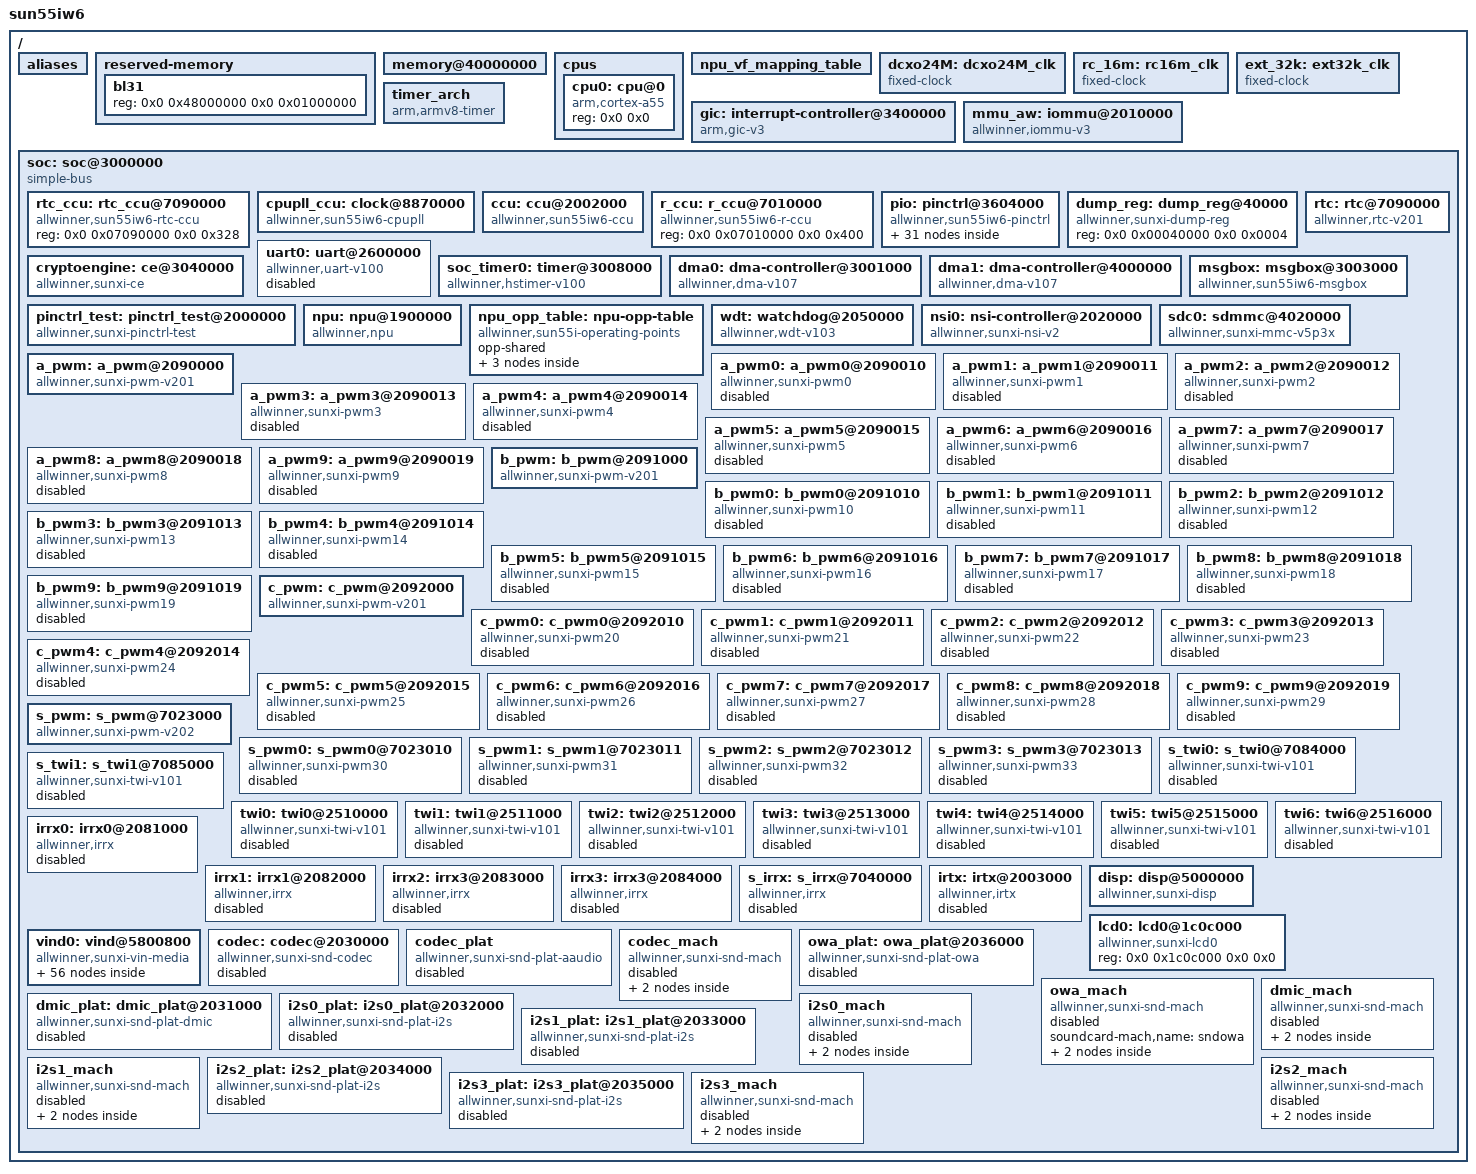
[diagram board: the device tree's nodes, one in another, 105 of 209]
// SPDX-License-Identifier: (GPL-2.0+ or MIT)
#include <dt-bindings/clock/sun55iw6-ccu.h>
#include <dt-bindings/clock/sun55iw6-rtc.h>
#include <dt-bindings/clock/sun55iw6-r-ccu.h>
#include <dt-bindings/gpio/gpio.h>
#include <dt-bindings/gpio/sun4i-gpio.h>
#include <dt-bindings/interrupt-controller/arm-gic.h>
#include <dt-bindings/reset/sun55iw6-ccu.h>
#include <dt-bindings/reset/sun55iw6-r-ccu.h>
#include <dt-bindings/power/a523-power.h>
#include <dt-bindings/phy/phy.h>
#include <dt-bindings/thermal/thermal.h>

/ {
	model = "sun55iw6";
	interrupt-parent = <&gic>;
	#address-cells = <2>;
	#size-cells = <2>;

	aliases {
		serial0 = &uart0;
		twi0 = &twi0;
		twi1 = &twi1;
		twi2 = &twi2;
		twi3 = &twi3;
		twi4 = &twi4;
		twi5 = &twi5;
		twi6 = &twi6;
		twi7 = &s_twi0;
		twi8 = &s_twi1;
		ir0 = &irrx0;
		ir1 = &irrx1;
		ir2 = &irrx2;
		ir3 = &irrx3;
		ir4 = &s_irrx;
	};

	reserved-memory {
		#address-cells = <2>;
		#size-cells = <2>;
		ranges;

		bl31 {
			reg = <0x0 0x48000000 0x0 0x01000000>;
		};
	};

	/* avoid panic when memory-node err(from uboot) */
	memory@40000000 {
		device_type = "memory";
		reg = <0x00000000 0x40000000 0x00000000 0x20000000>;
	};

	cpus {
		#address-cells = <2>;
		#size-cells = <0>;

		cpu0: cpu@0 {
			device_type = "cpu";
			compatible = "arm,cortex-a55";
			reg = <0x0 0x0>;
		};
	};

	npu_vf_mapping_table: npu_vf_mapping_table {
		table = <
			0x01 1
			0x02 2
			0x12 21
			0x04 3
			0x14 31
			0x05 4
			0x06 5
			>;
	};

	dcxo24M: dcxo24M_clk {
		#clock-cells = <0>;
		compatible = "fixed-clock";
		clock-frequency = <24000000>;
		clock-output-names = "dcxo24M";
	};

	rc_16m: rc16m_clk {
		#clock-cells = <0>;
		compatible = "fixed-clock";
		clock-frequency = <16000000>;
		clock-accuracy = <300000000>;
		clock-output-names = "rc-16m";
	};

	ext_32k: ext32k_clk {
		#clock-cells = <0>;
		compatible = "fixed-clock";
		clock-frequency = <32768>;
		clock-output-names = "ext-32k";
	};

	gic: interrupt-controller@3400000 {
		compatible = "arm,gic-v3";
		#interrupt-cells = <3>;
		#address-cells = <0>;
		interrupt-controller;
		reg = <0x0 0x03400000 0 0x10000>, /* GIC Dist */
		      <0x0 0x03460000 0 0xFF004>; /* GIC Re */
		interrupt-parent = <&gic>;
	};

	timer_arch {
		compatible = "arm,armv8-timer";
		interrupts = <GIC_PPI 13 (GIC_CPU_MASK_SIMPLE(4) | IRQ_TYPE_LEVEL_LOW)>,
			   <GIC_PPI 14 (GIC_CPU_MASK_SIMPLE(4) | IRQ_TYPE_LEVEL_LOW)>,
			   <GIC_PPI 11 (GIC_CPU_MASK_SIMPLE(4) | IRQ_TYPE_LEVEL_LOW)>,
			   <GIC_PPI 10 (GIC_CPU_MASK_SIMPLE(4) | IRQ_TYPE_LEVEL_LOW)>;
		clock-frequency = <24000000>;
		interrupt-parent = <&gic>;
		arm,no-tick-in-suspend;
	};

	mmu_aw: iommu@2010000 {
		compatible = "allwinner,iommu-v3";
		reg = <0x0 0x02010000 0x0 0x1000>;
		interrupts = <GIC_SPI 65 IRQ_TYPE_LEVEL_HIGH>;
		interrupt-names = "iommu-irq";
		clocks = <&ccu CLK_IOMMU>;
		clock-names = "iommu";
		/* clock-frequency = <24000000>; */
		#iommu-cells = <2>;
		version=<0x17>;
		tlb_prefetch = <0x3007f>;
		tlb_invalid_mode = <0x1>;
		ptw_invalid_mode = <0x1>;
		masters = "ISP", "CSI", "VE0", "RESERVED", "G2D",
			"DE", "E907", "DEBUG_MODE";
		valid_masters=<7>;
	};

	soc: soc@3000000 {
		compatible = "simple-bus";
		#address-cells = <2>;
		#size-cells = <2>;
		ranges;

		rtc_ccu: rtc_ccu@7090000 {
			compatible = "allwinner,sun55iw6-rtc-ccu";
			reg = <0x0 0x07090000 0x0 0x328>;
			#clock-cells = <1>;
			#reset-cells = <1>;
		};

		cpupll_ccu: clock@8870000 {
			compatible = "allwinner,sun55iw6-cpupll";
			reg = <0x0 0x08870000 0x0 0x4000>;
			#clock-cells = <1>;
			#reset-cells = <1>;
			pll_step = <0x9>;
			/* pll_ssc will divid pll_ssc_scale in code
			 * keep value 0 < pll_ssc < 10
			 */
			pll_ssc_scale = <0xa>;
			pll_ssc = <0x1>;
		};

		ccu: ccu@2002000 {
			compatible = "allwinner,sun55iw6-ccu";
			reg = <0x0 0x02002000 0x0 0x2000>;
			clocks = <&dcxo24M>, <&rtc_ccu CLK_OSC32K>, <&rc_16m>;
			clock-names = "hosc", "losc", "iosc";
			#clock-cells = <1>;
			#reset-cells = <1>;
		};

		r_ccu: r_ccu@7010000 {
			compatible = "allwinner,sun55iw6-r-ccu";
			reg = <0x0 0x07010000 0x0 0x400>;
			#clock-cells = <1>;
			#reset-cells = <1>;
		};

		pio: pinctrl@3604000 {
			//#address-cells = <1>;
			//#size-cells = <0>;
			compatible = "allwinner,sun55iw6-pinctrl";
			reg = <0x0 0x03604000 0x0 0x600>;
			interrupts = <GIC_SPI 67 IRQ_TYPE_LEVEL_HIGH>,
				     <GIC_SPI 69 IRQ_TYPE_LEVEL_HIGH>,
				     <GIC_SPI 71 IRQ_TYPE_LEVEL_HIGH>,
				     <GIC_SPI 73 IRQ_TYPE_LEVEL_HIGH>,
				     <GIC_SPI 77 IRQ_TYPE_LEVEL_HIGH>,
				     <GIC_SPI 79 IRQ_TYPE_LEVEL_HIGH>;
			clocks = <&ccu CLK_APB1>, <&dcxo24M>, <&rtc_ccu CLK_OSC32K>;
			clock-names = "apb", "hosc", "losc";
			gpio-controller;
			#gpio-cells = <3>;
			interrupt-controller;
			#interrupt-cells = <3>;

			test_pins_a: test_pins@0 {
				pins = "PB0", "PB1";
				function = "test";
				drive-strength = <10>;
				bias-pull-up;
			};

			test_pins_b: test_pins@1 {
				pins = "PB0", "PB1";
				function = "gpio_in";
			};

			sdc0_pins_a: sdc0@0 {
				pins = "PF0", "PF1", "PF2",
						"PF3", "PF4", "PF5";
				function = "sdc0";
				drive-strength = <40>;
				bias-pull-up;
				power-source = <3300>;
			};

			sdc0_pins_b: sdc0@1 {
				pins = "PF0", "PF1", "PF2",
						"PF3", "PF4", "PF5";
				function = "sdc0";
				drive-strength = <40>;
				bias-pull-up;
				power-source = <1800>;
			};

			sdc0_pins_c: sdc0@2 {
				pins = "PF0", "PF1", "PF2",
				"PF3", "PF4", "PF5";
				function = "gpio_in";
			};

			/* TODO: add jtag pin */
			sdc0_pins_d: sdc0@3 {
				pins = "PF2", "PF4";
				function = "uart0";
				drive-strength = <10>;
				bias-pull-up;
			};

			sdc0_pins_e: sdc0@4 {
				pins = "PF0", "PF1", "PF3",
						"PF5";
				function = "jtag";
				drive-strength = <10>;
				bias-pull-up;
			};

			csi_mclk0_pins_a: csi_mclk0@0 {
				pins = "PE0";
				function = "mipi0";
				drive-strength = <10>;
			};

			csi_mclk0_pins_b: csi_mclk0@1 {
				pins = "PE0";
				function = "gpio_in";
			};

			csi_mclk1_pins_a: csi_mclk1@0 {
				pins = "PE5";
				function = "mipi1";
				drive-strength = <10>;
			};

			csi_mclk1_pins_b: csi_mclk1@1 {
				pins = "PE5";
				function = "gpio_in";
			};

			csi_mclk2_pins_a: csi_mclk2@0 {
				pins = "PE15";
				function = "mipi2";
				drive-strength = <10>;
			};

			csi_mclk2_pins_b: csi_mclk2@1 {
				pins = "PE15";
				function = "gpio_in";
			};

			csi_mclk3_pins_a: csi_mclk3@0 {
				pins = "PE10";
				function = "mipi3";
				drive-strength = <10>;
			};

			csi_mclk3_pins_b: csi_mclk3@1 {
				pins = "PE10";
				function = "gpio_in";
			};

			ncsi_bt656_pins_a: ncsi_BT656@0 {
				pins = "PK20", "PK22", "PK23",
				"PK4", "PK5", "PK6", "PK7",
				"PK8", "PK9", "PK10", "PK11";
				function = "ncsi";
				drive-strength = <10>;
			};

			ncsi_bt656_pins_b: ncsi_BT656@1 {
				pins = "PK20", "PK22", "PK23",
				"PK4", "PK5", "PK6", "PK7",
				"PK8", "PK9", "PK10", "PK11";
				function = "gpio_in";
			};

			ncsi_bt1120_pins_a: ncsi_BT1120@0 {
				pins = "PK20", "PK22", "PK23",
				"PK4", "PK5", "PK6", "PK7",
				"PK8", "PK9", "PK10", "PK11",
				"PK12", "PK13", "PK14", "PK15",
				"PK16", "PK17", "PK18", "PK19";
				function = "ncsi";
				drive-strength = <10>;
			};

			ncsi_bt1120_pins_b: ncsi_BT1120@1 {
				pins = "PK20", "PK22", "PK23",
				"PK4", "PK5", "PK6", "PK7",
				"PK8", "PK9", "PK10", "PK11",
				"PK12", "PK13", "PK14", "PK15",
				"PK16", "PK17", "PK18", "PK19";
				function = "gpio_in";
			};

			mipia_pins_a: mipia@0 {
				pins = "PK0", "PK1", "PK2",
					"PK3", "PK4", "PK5";
				function = "mcsia";
				drive-strength = <10>;

			};

			mipia_pins_b: mipia@1 {
				pins = "PK0", "PK1", "PK2",
					"PK3", "PK4", "PK5";
				function = "gpio_in";
			};

			mipib_pins_a: mipib@0 {
				pins = "PK6", "PK7", "PK8",
					"PK9", "PK10", "PK11";
				function = "mcsib";
				drive-strength = <10>;
			};

			mipib_pins_b: mipib@1 {
				pins = "PK6", "PK7", "PK8",
					"PK9", "PK10", "PK11";
				function = "gpio_in";

			};

			mipib_4lane_pins_a: mipib_4lane@0 {
				pins = "PK6", "PK7", "PK8",
					"PK9", "PK10", "PK11";
				function = "mcsib";
				drive-strength = <10>;
			};

			mipib_4lane_pins_b: mipib_4lane@1 {
				pins = "PK6", "PK7", "PK8",
					"PK9", "PK10", "PK11";
				function = "gpio_in";
			};

			mipic_pins_a: mipic@0 {
				pins = "PK12", "PK13", "PK14",
					"PK15", "PK16", "PK17";
				function = "mcsic";
				drive-strength = <10>;

			};

			mipic_pins_b: mipic@1 {
				pins = "PK12", "PK13", "PK14",
					"PK15", "PK16", "PK17";
				function = "gpio_in";
			};

			mipid_pins_a: mipid@0 {
				pins = "PK18", "PK19", "PK20",
					"PK21", "PK22", "PK23";
				function = "mcsid";
				drive-strength = <10>;
			};

			mipid_pins_b: mipid@1 {
				pins = "PK18", "PK19", "PK20",
					"PK21", "PK22", "PK23";
				function = "gpio_in";

			};

			mipid_4lane_pins_a: mipid_4lane@0 {
				pins = "PK18", "PK19", "PK20",
					"PK21", "PK22", "PK23";
				function = "mcsid";
				drive-strength = <10>;
			};

			mipid_4lane_pins_b: mipid_4lane@1 {
				pins = "PK18", "PK19", "PK20",
					"PK21", "PK22", "PK23";
				function = "gpio_in";
			};
		};

		dump_reg: dump_reg@40000 {
			compatible = "allwinner,sunxi-dump-reg";
			reg = <0x0 0x00040000 0x0 0x0004>;
		};

		uart0: uart@2600000 {
			compatible = "allwinner,uart-v100";
			reg = <0x0 0x02600000 0x0 0x400>;
			interrupts = <GIC_SPI 2 IRQ_TYPE_LEVEL_HIGH>;
			clocks = <&ccu CLK_BUS_UART0>;
			resets = <&ccu RST_BUS_UART0>;
			uart0_port = <0>;
			uart0_type = <2>;
			status = "disabled";
		};

		cryptoengine: ce@3040000 {
			compatible = "allwinner,sunxi-ce";
			device_name = "ce";
			reg = <0x0 0x03040000 0x0 0x800>, /* non-secure space */
				<0x0 0x03040800 0x0 0x800>; /* secure space */
			interrupts = <GIC_SPI 52 IRQ_TYPE_EDGE_RISING>, /*non-secure*/
				<GIC_SPI 53 IRQ_TYPE_EDGE_RISING>; /* secure*/
			clock-frequency = <400000000>; /* 400MHz */
			clocks = <&ccu CLK_BUS_CE>, <&ccu CLK_CE>, <&ccu CLK_CE_MBUS_GATE>,
				 <&ccu CLK_PLL_PERI0_400M>, <&ccu CLK_CE_SYS>;
			clock-names = "bus_ce", "ce_clk", "mbus_ce", "clk_src", "ce_sys_clk";
			resets = <&ccu RST_BUS_CE>;
			status = "okay";
		};

		rtc: rtc@7090000 {
			compatible = "allwinner,rtc-v201";
			device_type = "rtc";
			wakeup-source;
			reg = <0x0 0x07090000 0x0 0x320>;
			interrupts = <GIC_SPI 200 IRQ_TYPE_LEVEL_HIGH>;
			clocks = <&r_ccu CLK_RTC>, <&rtc_ccu CLK_RTC_1K>, <&rtc_ccu CLK_RTC_SPI>;
			clock-names = "r-ahb-rtc", "rtc-1k", "rtc-spi";
			resets = <&r_ccu RST_BUS_RTC>;
			gpr_cur_pos = <6>;
			gpr_bootcount_pos = <7>;
		};

		soc_timer0: timer@3008000 {
			compatible = "allwinner,hstimer-v100";
			device_type = "soc_timer";
			reg = <0x0 0x03008000 0x0 0x400>;
			interrupt-parent = <&gic>;
			interrupts = <GIC_SPI 55 IRQ_TYPE_LEVEL_HIGH>;
			clock-names = "parent", "bus", "timer0-mod", "timer1-mod";
			clocks = <&dcxo24M>, <&ccu CLK_BUS_TIMER>, <&ccu CLK_TIMER0>, <&ccu CLK_TIMER1>;
			resets = <&ccu RST_BUS_TIME>;
		};

		dma0: dma-controller@3001000 {
			compatible = "allwinner,dma-v107";
			reg = <0x0 0x3001000 0x0 0x2000>;
			interrupts = <GIC_SPI 50 IRQ_TYPE_LEVEL_HIGH>,
				     <GIC_SPI 235 IRQ_TYPE_LEVEL_HIGH>;
			clocks = <&ccu CLK_DMA0>, <&ccu CLK_DMA0_MBUS_GATE>;
			clock-names = "bus", "mbus";
			dma-channels = <16>;
			dma-requests = <64>;
			resets = <&ccu RST_BUS_DMA0>;
			#dma-cells = <1>;
		};

		dma1: dma-controller@4000000 {
			compatible = "allwinner,dma-v107";
			reg = <0x0 0x4000000 0x0 0x2000>;
			interrupts = <GIC_SPI 164 IRQ_TYPE_LEVEL_HIGH>;
			clocks = <&ccu CLK_DMA1>, <&ccu CLK_DMA1_MBUS_GATE>;
			clock-names = "bus", "mbus";
			dma-channels = <16>;
			dma-requests = <64>;
			resets = <&ccu RST_BUS_DMA1>;
			#dma-cells = <1>;
		};

		/*
		 * channel4~7  : arm -> cpus
		 * channel8~11 : arm -> RV
		 */
		msgbox: msgbox@3003000 {
			compatible = "allwinner,sun55iw6-msgbox";
			#mbox-cells = <1>;
			reg = <0x0 0x03003000 0x0 0x1000>,
			      <0x0 0x07094000 0x0 0x1000>,
			      <0x0 0x01a06000 0x0 0x1000>;
			interrupts = <GIC_SPI 0 IRQ_TYPE_LEVEL_HIGH>,
				     <GIC_SPI 215 IRQ_TYPE_LEVEL_HIGH>,
				     <GIC_SPI 183 IRQ_TYPE_LEVEL_HIGH>;
			clocks = <&ccu CLK_MSGBOX0>;
			clock-names = "msgbox";
			resets = <&ccu RST_BUS_MSGBOX0>;
			reset-names = "rst";
			local_id = <0>;
			status = "okay";
		};

		pinctrl_test: pinctrl_test@2000000 {
		      reg = <0x0 0x0 0x0 0x0>;
		      compatible = "allwinner,sunxi-pinctrl-test";
		      device_type = "pinctrl-test";
		      pinctrl-0 = <&test_pins_a>;
		      pinctrl-1 = <&test_pins_b>;
		      pinctrl-names = "default", "sleep";
		      test-gpios = <&pio PB 4 GPIO_ACTIVE_LOW>;
		      suspend-gpios = <&pio PB 5 GPIO_ACTIVE_LOW>;
		      wakeup-source;
		      interrupt-parent = <&pio>;
		      interrupts = <PB 6 IRQ_TYPE_LEVEL_HIGH>;
		};

		npu: npu@1900000 {
			compatible = "allwinner,npu";
			reg = <0x0 0x01900000 0x0 0x1000>;
			device_type = "npu";
			dev_name = "npu";
			interrupts = <GIC_SPI 116 IRQ_TYPE_LEVEL_HIGH>;
			interrupt-names = "npu";
			clocks = <&ccu CLK_NPU>, <&ccu CLK_PLL_NPU_4X>;
			clock-names = "clk_npu", "clk_parent";
			resets = <&ccu RST_BUS_NPU_CORE>, <&ccu RST_BUS_NPU_AXI>, <&ccu RST_BUS_NPU_AHB>;
			reset-names = "npu_rst", "npu_axi_rst", "npu_ahb_rst";
			/*
			 * power-domains = <&pd Ti533_PD_NPU>;
			 */
			npu-vf = <696>;
			status = "okay";
		};

		npu_opp_table: npu-opp-table {
			compatible = "allwinner,sun55i-operating-points";
			opp-shared;
			npu_opp_table_546: opp-546 {
				opp-hz = <546000000>;
				opp-microvolt-vf1 = <900000>;
			};

			npu_opp_table_696: opp-696 {
				opp-hz = <696000000>;
				opp-microvolt-vf1 = <920000>;
			};
			npu_opp_table_900: opp-900 {
				opp-hz = <900000000>;
				opp-microvolt-vf1 = <1050000>;
			};
		};

		wdt: watchdog@2050000 {
			compatible = "allwinner,wdt-v103";
			reg = <0x0 0x02050000 0x0 0x20>;
			interrupts = <GIC_SPI 63 IRQ_TYPE_LEVEL_HIGH>;  /* In GIC Spec */
		};

		nsi0: nsi-controller@2020000 {
			compatible = "allwinner,sunxi-nsi-v2";
			interrupts = <GIC_SPI 43 IRQ_TYPE_LEVEL_HIGH>;
			reg = <0x0 0x02020000 0x0 0x10000>;
			clocks = <&ccu CLK_PLL_DDR>, <&ccu CLK_MBUS>, <&ccu CLK_LBC>,
				<&ccu CLK_NSI>, <&ccu CLK_PLL_DDR>,
				<&ccu CLK_GIC>, <&ccu CLK_AHB>,
				<&ccu CLK_SERDES_AXI>, <&ccu CLK_GMAC_NSI>, <&ccu CLK_DRAM>;
			clock-names = "pll", "bus", "lbc",
					"nsi", "nsi-p",
					"gic", "ahb", "serdes", "gmac", "dram";
			resets = <&ccu RST_BUS_NSI>, <&ccu RST_BUS_NSI_CFG>;
			reset-names = "bus_nsi", "bus_nsi_cfg";
			clock-frequency = <600000000>, <600000000>;
			#nsi-cells = <1>;
			ra_pmu_data_unit = <64>;
			clk_path_type = <1>;
			topology_type = <2>;
			channel_type = <1>;
			master_clks = <0 9>, <1 5>, <2 1>, <3 1>, <4 1>, <5 1>, <6 1>, <7 3>, <8 1>, <9 7>,
					<10 1>, <11 3>, <12 2>, <13 8>, <14 3>, <15 3>, <16 1>, <17 3>, <18 3>, <19 6>,
					<20 6>, <21 6>, <22 6>, <23 6>, <24 6>, <25 6>;
		};

		sdc0: sdmmc@4020000 {
			compatible = "allwinner,sunxi-mmc-v5p3x";
			device_type = "sdc0";
			reg = <0x0 0x04020000 0x0 0x1000>;
			interrupts = <GIC_SPI 40 IRQ_TYPE_LEVEL_HIGH>;
						clocks = <&dcxo24M>,
						<&ccu CLK_PLL_PERI1_400M>,
						<&ccu CLK_PLL_PERI1_300M>,
						<&ccu CLK_SMHC0>,
						<&ccu CLK_BUS_SMHC0>;
			clock-names = "osc24m","pll_periph","pll_periph_2","mmc","ahb";
			resets = <&ccu RST_BUS_SMHC0>;
			reset-names = "rst";
			pinctrl-names = "default","mmc_1v8","sleep","uart_jtag";
			pinctrl-0 = <&sdc0_pins_a>;
			pinctrl-1 = <&sdc0_pins_b>;
			pinctrl-2 = <&sdc0_pins_c>;
			pinctrl-3 = <&sdc0_pins_d &sdc0_pins_e>;
			max-frequency = <50000000>;
			bus-width = <4>;
			req-page-count = <2>;
			/*non-removable;*/
			/*broken-cd;*/
			/*cd-inverted*/
			/*cd-gpios = <&pio PF 6 GPIO_ACTIVE_LOW>;*/
			/* vmmc-supply = <&reg_3p3v>;*/
			/* vqmc-supply = <&reg_3p3v>;*/
			/* vdmc-supply = <&reg_3p3v>;*/
			/*vmmc = "vcc-card";*/
			/*vqmc = "";*/
			/*vdmc = "";*/
			cap-sd-highspeed;
			cap-wait-while-busy;
			/*sd-uhs-sdr50;*/
			/*sd-uhs-ddr50;*/
			/*cap-sdio-irq;*/
			/*keep-power-in-suspend;*/
			/*ignore-pm-notify;*/
			/*sunxi-power-save-mode;*/
			/*sunxi-dly-400k = <1 0 0 0>; */
			/*sunxi-dly-26M  = <1 0 0 0>;*/
			/*sunxi-dly-52M  = <1 0 0 0>;*/
			/*sunxi-dly-52M-ddr4  = <1 0 0 0>;*/
			/*sunxi-dly-52M-ddr8  = <1 0 0 0>;*/
			/*sunxi-dly-104M  = <1 0 0 0>;*/
			/*sunxi-dly-208M  = <1 0 0 0>;*/
			/*sunxi-dly-104M-ddr  = <1 0 0 0>;*/
			/*sunxi-dly-208M-ddr  = <1 0 0 0>;*/
			ctl-spec-caps = <0x408>;
			status = "okay";
		};

		a_pwm: a_pwm@2090000 {
			#pwm-cells = <0x3>;
			compatible = "allwinner,sunxi-pwm-v201";
			reg = <0x0 0x02090000 0x0 0x400>;
			clocks = <&ccu CLK_PWM0>;
			interrupts = <GIC_SPI 19 IRQ_TYPE_LEVEL_HIGH>;
			resets = <&ccu RST_BUS_PWM0>;
			pwm-number = <10>;
			pwm-base = <0x0>;
			sunxi-pwms = <&a_pwm0>, <&a_pwm1>, <&a_pwm2>, <&a_pwm3>, <&a_pwm4>,
			<&a_pwm5>, <&a_pwm6>, <&a_pwm7>, <&a_pwm8>, <&a_pwm9>;
			status = "okay";
		};

		a_pwm0: a_pwm0@2090010 {
			compatible = "allwinner,sunxi-pwm0";
			reg = <0x0 0x02090010 0x0 0x4>;
			reg_base = <0x02090000>;
			status = "disabled";
		};

		a_pwm1: a_pwm1@2090011 {
			compatible = "allwinner,sunxi-pwm1";
			reg = <0x0 0x02090011 0x0 0x4>;
			reg_base = <0x02090000>;
			status = "disabled";
		};

		a_pwm2: a_pwm2@2090012 {
			compatible = "allwinner,sunxi-pwm2";
			reg = <0x0 0x02090012 0x0 0x4>;
			reg_base = <0x02090000>;
			status = "disabled";
		};

		a_pwm3: a_pwm3@2090013 {
			compatible = "allwinner,sunxi-pwm3";
			reg = <0x0 0x02090013 0x0 0x4>;
			reg_base = <0x02090000>;
			status = "disabled";
		};

		a_pwm4: a_pwm4@2090014 {
			compatible = "allwinner,sunxi-pwm4";
			reg = <0x0 0x02090014 0x0 0x4>;
			reg_base = <0x02090000>;
			status = "disabled";
		};

		a_pwm5: a_pwm5@2090015 {
			compatible = "allwinner,sunxi-pwm5";
			reg = <0x0 0x02090015 0x0 0x4>;
			reg_base = <0x02090000>;
			status = "disabled";
		};

		a_pwm6: a_pwm6@2090016 {
			compatible = "allwinner,sunxi-pwm6";
			reg = <0x0 0x02090016 0x0 0x4>;
			reg_base = <0x02090000>;
			status = "disabled";
		};

		a_pwm7: a_pwm7@2090017 {
			compatible = "allwinner,sunxi-pwm7";
			reg = <0x0 0x02090017 0x0 0x4>;
			reg_base = <0x02090000>;
			status = "disabled";
		};

		a_pwm8: a_pwm8@2090018 {
			compatible = "allwinner,sunxi-pwm8";
			reg = <0x0 0x02090018 0x0 0x4>;
			reg_base = <0x02090000>;
			status = "disabled";
		};

		a_pwm9: a_pwm9@2090019 {
			compatible = "allwinner,sunxi-pwm9";
			reg = <0x0 0x02090019 0x0 0x4>;
			reg_base = <0x02090000>;
			status = "disabled";
		};

		b_pwm: b_pwm@2091000 {
			#pwm-cells = <0x3>;
			compatible = "allwinner,sunxi-pwm-v201";
			reg = <0x0 0x02091000 0x0 0x400>;
			clocks = <&ccu CLK_PWM1>;
			interrupts = <GIC_SPI 142 IRQ_TYPE_LEVEL_HIGH>;
			resets = <&ccu RST_BUS_PWM1>;
			pwm-number = <10>;
			pwm-base = <0xa>;
			sunxi-pwms = <&b_pwm0>, <&b_pwm1>, <&b_pwm2>, <&b_pwm3>,
			<&b_pwm4>, <&b_pwm5>, <&b_pwm6>, <&b_pwm7>, <&b_pwm8>, <&b_pwm9>;
			status = "okay";
		};

		b_pwm0: b_pwm0@2091010 {
			compatible = "allwinner,sunxi-pwm10";
			reg = <0x0 0x02091010 0x0 0x4>;
			reg_base = <0x02091000>;
			status = "disabled";
		};

		b_pwm1: b_pwm1@2091011 {
			compatible = "allwinner,sunxi-pwm11";
			reg = <0x0 0x02091011 0x0 0x4>;
			reg_base = <0x02091000>;
			status = "disabled";
		};

		b_pwm2: b_pwm2@2091012 {
			compatible = "allwinner,sunxi-pwm12";
			reg = <0x0 0x02091012 0x0 0x4>;
			reg_base = <0x02091000>;
			status = "disabled";
		};

		b_pwm3: b_pwm3@2091013 {
			compatible = "allwinner,sunxi-pwm13";
			reg = <0x0 0x02091013 0x0 0x4>;
			reg_base = <0x02091000>;
			status = "disabled";
		};

		b_pwm4: b_pwm4@2091014 {
			compatible = "allwinner,sunxi-pwm14";
			reg = <0x0 0x02091014 0x0 0x4>;
			reg_base = <0x02091000>;
			status = "disabled";
		};

		b_pwm5: b_pwm5@2091015 {
			compatible = "allwinner,sunxi-pwm15";
			reg = <0x0 0x02091015 0x0 0x4>;
			reg_base = <0x02091000>;
			status = "disabled";
		};

		b_pwm6: b_pwm6@2091016 {
			compatible = "allwinner,sunxi-pwm16";
			reg = <0x0 0x02091016 0x0 0x4>;
			reg_base = <0x02091000>;
			status = "disabled";
		};

		b_pwm7: b_pwm7@2091017 {
			compatible = "allwinner,sunxi-pwm17";
			reg = <0x0 0x02091017 0x0 0x4>;
			reg_base = <0x02091000>;
			status = "disabled";
		};

		b_pwm8: b_pwm8@2091018 {
			compatible = "allwinner,sunxi-pwm18";
			reg = <0x0 0x02091018 0x0 0x4>;
			reg_base = <0x02091000>;
			status = "disabled";
		};

		b_pwm9: b_pwm9@2091019 {
			compatible = "allwinner,sunxi-pwm19";
			reg = <0x0 0x02091019 0x0 0x4>;
			reg_base = <0x02091000>;
			status = "disabled";
		};

		c_pwm: c_pwm@2092000 {
			#pwm-cells = <0x3>;
			compatible = "allwinner,sunxi-pwm-v201";
			reg = <0x0 0x02092000 0x0 0x400>;
			clocks = <&ccu CLK_PWM2>;
			interrupts = <GIC_SPI 211 IRQ_TYPE_LEVEL_HIGH>;
			resets = <&ccu RST_BUS_PWM2>;
			pwm-number = <10>;
			pwm-base = <0x14>;
			sunxi-pwms = <&c_pwm0>, <&c_pwm1>, <&c_pwm2>, <&c_pwm3>,
			<&c_pwm4>, <&c_pwm5>, <&c_pwm6>, <&c_pwm7>, <&c_pwm8>, <&c_pwm9>;
			status = "okay";
		};

		c_pwm0: c_pwm0@2092010 {
			compatible = "allwinner,sunxi-pwm20";
			reg = <0x0 0x02092010 0x0 0x4>;
			reg_base = <0x02092000>;
			status = "disabled";
		};

		c_pwm1: c_pwm1@2092011 {
			compatible = "allwinner,sunxi-pwm21";
			reg = <0x0 0x02092011 0x0 0x4>;
			reg_base = <0x02092000>;
			status = "disabled";
		};

		c_pwm2: c_pwm2@2092012 {
			compatible = "allwinner,sunxi-pwm22";
			reg = <0x0 0x02092012 0x0 0x4>;
			reg_base = <0x02092000>;
			status = "disabled";
		};

		c_pwm3: c_pwm3@2092013 {
			compatible = "allwinner,sunxi-pwm23";
			reg = <0x0 0x02092013 0x0 0x4>;
			reg_base = <0x02092000>;
			status = "disabled";
		};

		c_pwm4: c_pwm4@2092014 {
			compatible = "allwinner,sunxi-pwm24";
			reg = <0x0 0x02092014 0x0 0x4>;
			reg_base = <0x02092000>;
			status = "disabled";
		};

		c_pwm5: c_pwm5@2092015 {
			compatible = "allwinner,sunxi-pwm25";
			reg = <0x0 0x02092015 0x0 0x4>;
			reg_base = <0x02092000>;
			status = "disabled";
		};

		c_pwm6: c_pwm6@2092016 {
			compatible = "allwinner,sunxi-pwm26";
			reg = <0x0 0x02092016 0x0 0x4>;
			reg_base = <0x02092000>;
			status = "disabled";
		};

		c_pwm7: c_pwm7@2092017 {
			compatible = "allwinner,sunxi-pwm27";
			reg = <0x0 0x02092017 0x0 0x4>;
			reg_base = <0x02092000>;
			status = "disabled";
		};

		c_pwm8: c_pwm8@2092018 {
			compatible = "allwinner,sunxi-pwm28";
			reg = <0x0 0x02092018 0x0 0x4>;
			reg_base = <0x02092000>;
			status = "disabled";
		};

		c_pwm9: c_pwm9@2092019 {
			compatible = "allwinner,sunxi-pwm29";
			reg = <0x0 0x02092019 0x0 0x4>;
			reg_base = <0x02092000>;
			status = "disabled";
		};

		s_pwm: s_pwm@7023000 {
			#pwm-cells = <0x3>;
			compatible = "allwinner,sunxi-pwm-v202";
			reg = <0x0 0x07023000 0x0 0x400>;
			clocks = <&r_ccu CLK_R_PWM>,<&r_ccu CLK_R_BUS_PWM>;
			interrupts = <GIC_SPI 207 IRQ_TYPE_LEVEL_HIGH>;
			clock-names = "clk_pwm","clk_bus_pwm";
			resets = <&r_ccu RST_BUS_R_PWM>;
			pwm-number = <4>;
			pwm-base = <0x1e>;
			sunxi-pwms = <&s_pwm0>, <&s_pwm1>, <&s_pwm2>, <&s_pwm3>;
			status = "okay";
		};

		s_pwm0: s_pwm0@7023010 {
			compatible = "allwinner,sunxi-pwm30";
			reg = <0x0 0x07023010 0x0 0x4>;
			reg_base = <0x07023000>;
			status = "disabled";
		};

		s_pwm1: s_pwm1@7023011 {
			compatible = "allwinner,sunxi-pwm31";
			reg = <0x0 0x07023011 0x0 0x4>;
			reg_base = <0x07023000>;
			status = "disabled";
		};

		s_pwm2: s_pwm2@7023012 {
			compatible = "allwinner,sunxi-pwm32";
			reg = <0x0 0x07023012 0x0 0x4>;
			reg_base = <0x07023000>;
			status = "disabled";
		};

		s_pwm3: s_pwm3@7023013 {
			compatible = "allwinner,sunxi-pwm33";
			reg = <0x0 0x07023013 0x0 0x4>;
			reg_base = <0x07023000>;
			status = "disabled";
		};

		s_twi0: s_twi0@7084000 {
			#address-cells = <1>;
			#size-cells = <0>;
			compatible = "allwinner,sunxi-twi-v101";
			device_type = "s_twi0";
			reg = <0x0 0x07084000 0x0 0x400>;
			interrupts = <GIC_SPI 207 IRQ_TYPE_LEVEL_HIGH>;
			clocks = <&r_ccu CLK_R_TWI0>;
			clock-names = "bus";
			resets = <&r_ccu RST_BUS_R_TWI0>;
			dmas = <&dma0 49>, <&dma0 49>;
			dma-names = "tx", "rx";
			status = "disabled";
		};

		s_twi1: s_twi1@7085000 {
			#address-cells = <1>;
			#size-cells = <0>;
			compatible = "allwinner,sunxi-twi-v101";
			device_type = "s_twi1";
			reg = <0x0 0x07085000 0x0 0x400>;
			interrupts = <GIC_SPI 208 IRQ_TYPE_LEVEL_HIGH>;
			clocks = <&r_ccu CLK_R_TWI1>;
			clock-names = "bus";
			resets = <&r_ccu RST_BUS_R_TWI1>;
			dmas = <&dma0 50>, <&dma0 50>;
			dma-names = "tx", "rx";
			status = "disabled";
		};

		twi0: twi0@2510000 {
			#address-cells = <1>;
			#size-cells = <0>;
			compatible = "allwinner,sunxi-twi-v101";
			device_type = "twi0";
			reg = <0x0 0x02510000 0x0 0x400>;
			interrupts = <GIC_SPI 10 IRQ_TYPE_LEVEL_HIGH>;
			clocks = <&ccu CLK_TWI0>;
			clock-names = "bus";
			resets = <&ccu RST_BUS_TWI0>;
			dmas = <&dma0 43>, <&dma0 43>;
			dma-names = "tx", "rx";
			status = "disabled";
		};

		twi1: twi1@2511000 {
			#address-cells = <1>;
			#size-cells = <0>;
			compatible = "allwinner,sunxi-twi-v101";
			device_type = "twi1";
			reg = <0x0 0x02511000 0x0 0x400>;
			interrupts = <GIC_SPI 11 IRQ_TYPE_LEVEL_HIGH>;
			clocks = <&ccu CLK_TWI1>;
			clock-names = "bus";
			resets = <&ccu RST_BUS_TWI1>;
			dmas = <&dma0 44>, <&dma0 44>;
			dma-names = "tx", "rx";
			status = "disabled";
		};

		twi2: twi2@2512000 {
			#address-cells = <1>;
			#size-cells = <0>;
			compatible = "allwinner,sunxi-twi-v101";
			device_type = "twi2";
			reg = <0x0 0x02512000 0x0 0x400>;
			interrupts = <GIC_SPI 12 IRQ_TYPE_LEVEL_HIGH>;
			clocks = <&ccu CLK_TWI2>;
			clock-names = "bus";
			resets = <&ccu RST_BUS_TWI2>;
			dmas = <&dma0 45>, <&dma0 45>;
			dma-names = "tx", "rx";
			status = "disabled";
		};

		twi3: twi3@2513000 {
			#address-cells = <1>;
			#size-cells = <0>;
			compatible = "allwinner,sunxi-twi-v101";
			device_type = "twi3";
			reg = <0x0 0x02513000 0x0 0x400>;
			interrupts = <GIC_SPI 13 IRQ_TYPE_LEVEL_HIGH>;
			clocks = <&ccu CLK_TWI3>;
			clock-names = "bus";
			resets = <&ccu RST_BUS_TWI3>;
			dmas = <&dma0 46>, <&dma0 46>;
			dma-names = "tx", "rx";
			status = "disabled";
		};

		twi4: twi4@2514000 {
			#address-cells = <1>;
			#size-cells = <0>;
			compatible = "allwinner,sunxi-twi-v101";
			device_type = "twi4";
			reg = <0x0 0x02514000 0x0 0x400>;
			interrupts = <GIC_SPI 14 IRQ_TYPE_LEVEL_HIGH>;
			clocks = <&ccu CLK_TWI4>;
			clock-names = "bus";
			resets = <&ccu RST_BUS_TWI4>;
			dmas = <&dma0 47>, <&dma0 47>;
			dma-names = "tx", "rx";
			status = "disabled";
		};

		twi5: twi5@2515000 {
			#address-cells = <1>;
			#size-cells = <0>;
			compatible = "allwinner,sunxi-twi-v101";
			device_type = "twi5";
			reg = <0x0 0x02515000 0x0 0x400>;
			interrupts = <GIC_SPI 15 IRQ_TYPE_LEVEL_HIGH>;
			clocks = <&ccu CLK_TWI5>;
			clock-names = "bus";
			resets = <&ccu RST_BUS_TWI5>;
			dmas = <&dma0 48>, <&dma0 48>;
			dma-names = "tx", "rx";
			status = "disabled";
		};

		twi6: twi6@2516000 {
			#address-cells = <1>;
			#size-cells = <0>;
			compatible = "allwinner,sunxi-twi-v101";
			device_type = "twi6";
			reg = <0x0 0x02516000 0x0 0x400>;
			interrupts = <GIC_SPI 155 IRQ_TYPE_LEVEL_HIGH>;
			clocks = <&ccu CLK_TWI6>;
			clock-names = "bus";
			resets = <&ccu RST_BUS_TWI6>;
			dmas = <&dma0 62>, <&dma0 62>;
			dma-names = "tx", "rx";
			status = "disabled";
		};

		irrx0: irrx0@2081000 {
			compatible = "allwinner,irrx";
			reg = <0x0 0x02081000 0x0 0x400>;
			interrupts = <GIC_SPI 27 IRQ_TYPE_LEVEL_HIGH>;
			clocks = <&ccu CLK_BUS_IRRX0>, <&dcxo24M>, <&ccu CLK_IRRX0>;
			clock-names = "bus", "pclk", "mclk";
			resets = <&ccu RST_BUS_IRRX0>;
			status = "disabled";
		};

		irrx1: irrx1@2082000 {
			compatible = "allwinner,irrx";
			reg = <0x0 0x02082000 0x0 0x400>;
			interrupts = <GIC_SPI 117 IRQ_TYPE_LEVEL_HIGH>;
			clocks = <&ccu CLK_BUS_IRRX1>, <&dcxo24M>, <&ccu CLK_IRRX1>;
			clock-names = "bus", "pclk", "mclk";
			resets = <&ccu RST_BUS_IRRX1>;
			status = "disabled";
		};

		irrx2: irrx3@2083000 {
			compatible = "allwinner,irrx";
			reg = <0x0 0x02083000 0x0 0x400>;
			interrupts = <GIC_SPI 118 IRQ_TYPE_LEVEL_HIGH>;
			clocks = <&ccu CLK_BUS_IRRX2>, <&dcxo24M>, <&ccu CLK_IRRX2>;
			clock-names = "bus", "pclk", "mclk";
			resets = <&ccu RST_BUS_IRRX2>;
			status = "disabled";
		};

		irrx3: irrx3@2084000 {
			compatible = "allwinner,irrx";
			reg = <0x0 0x02084000 0x0 0x400>;
			interrupts = <GIC_SPI 119 IRQ_TYPE_LEVEL_HIGH>;
			clocks = <&ccu CLK_BUS_IRRX3>, <&dcxo24M>, <&ccu CLK_IRRX3>;
			clock-names = "bus", "pclk", "mclk";
			resets = <&ccu RST_BUS_IRRX3>;
			status = "disabled";
		};

		s_irrx: s_irrx@7040000 {
			compatible = "allwinner,irrx";
			reg = <0x0 0x07040000 0x0 0x400>;
			interrupts = <GIC_SPI 210 IRQ_TYPE_LEVEL_HIGH>;
			clocks = <&r_ccu CLK_R_BUS_IRRX>, <&dcxo24M>, <&r_ccu CLK_R_IRRX>;
			clock-names = "bus", "pclk", "mclk";
			resets = <&r_ccu RST_BUS_R_IRRX>;
			status = "disabled";
		};

		irtx: irtx@2003000 {
			compatible = "allwinner,irtx";
			reg = <0x0 0x02003000 0x0 0x400>;
			interrupts = <GIC_SPI 26 IRQ_TYPE_LEVEL_HIGH>;
			clocks = <&ccu CLK_BUS_IRTX>, <&dcxo24M>, <&ccu CLK_IRTX>;
			clock-names = "bus", "pclk", "mclk";
			resets = <&ccu RST_BUS_IRTX>;
			status = "disabled";
		};

		disp: disp@5000000 {
			compatible = "allwinner,sunxi-disp";
			reg = <0x0 0x05000000 0x0 0x400000>, /*de*/
			      <0x0 0x05500000 0x0 0x1000>, /* display_if_top */
			      <0x0 0x05501000 0x0 0x1000>, /* tcon0 - tcon_lcd0 */
			      <0x0 0x05506000 0x0 0x1fff>; /* dsi0 */
			interrupts = <GIC_SPI 87 IRQ_TYPE_LEVEL_HIGH>, /* DE */
				     <GIC_SPI 88 IRQ_TYPE_LEVEL_HIGH>, /* DE freeze */
				     <GIC_SPI 90 IRQ_TYPE_LEVEL_HIGH>, /* tcon_lcd0 */
				     <GIC_SPI 91 IRQ_TYPE_LEVEL_HIGH>; /* dsi0 */
			clocks = <&ccu CLK_DE>,
				 <&ccu CLK_DE0>,
				 <&ccu CLK_VO0_TCONLCD0>,
				 <&ccu CLK_BUS_VO0_TCONLCD0>,
				 <&ccu CLK_DPSS>,
				 <&ccu CLK_DSI0>,
				 <&ccu CLK_BUS_DSI0>,
				 <&ccu CLK_VO0_COMBPHY0>;
			clock-names = 	"clk_de0",
					"clk_bus_de0",
					"clk_tcon0",
					"clk_bus_tcon0",
					"clk_bus_dpss_top0",
					"clk_mipi_dsi0",
					"clk_bus_mipi_dsi0",
					"clk_mipi_dsi_combphy0";
			resets = <&ccu RST_BUS_DE0>,
				 <&ccu RST_BUS_VO0_TCONLCD0>,
				 <&ccu RST_BUS_LVDS0>,
				 <&ccu RST_BUS_DP>,
				 <&ccu RST_BUS_VIDEO_OUT0>,
				 <&ccu RST_BUS_DSI0>;
			reset-names = 	"rst_bus_de0",
					"rst_bus_tcon0",
					"rst_bus_lvds0",
					"rst_bus_dpss_top0",
					"rst_bus_video_out0",
					"rst_bus_mipi_dsi0";
			assigned-clocks = <&ccu CLK_DE>,
							  <&ccu CLK_VO0_TCONLCD0>;
			assigned-clock-parents = <&ccu CLK_PLL_PERI0_600M>,
									 <&ccu CLK_PLL_VIDEO0_4X>;
			assigned-clock-rates = <300000000>;
			iommus = <&mmu_aw 5 0>;
			status = "okay";

			boot_disp = <0>;
			fb_base = <0>;
		};

		lcd0: lcd0@1c0c000 {
			compatible = "allwinner,sunxi-lcd0";
			/* Fake registers to avoid dtc compiling warnings */
			reg = <0x0 0x1c0c000 0x0 0x0>;
			pinctrl-names = "active","sleep";
		};

		vind0: vind@5800800 {
			compatible = "allwinner,sunxi-vin-media", "simple-bus";
			#address-cells = <2>;
			#size-cells = <2>;
			ranges;
			device_id = <0>;
			csi_top = <336000000>;
			csi_isp = <327000000>;
			reg = <0x0 0x05800800 0x0 0x200>,
				<0x0 0x05800000 0x0 0x800>,
				<0x0 0x05810000 0x0 0x100>;
			interrupts = <GIC_SPI 139 IRQ_TYPE_LEVEL_HIGH>;
			clocks = <&ccu CLK_CSI>, <&ccu CLK_PLL_VIDEO1_4X>,
				<&ccu CLK_CSI_MASTER0>, <&dcxo24M>, <&ccu CLK_PLL_VIDEO0_4X>,
				<&ccu CLK_CSI_MASTER1>, <&dcxo24M>, <&ccu CLK_PLL_VIDEO0_4X>,
				<&ccu CLK_CSI_MASTER2>, <&dcxo24M>, <&ccu CLK_PLL_VIDEO0_4X>,
				<&ccu CLK_CSI_MASTER3>, <&dcxo24M>, <&ccu CLK_PLL_VIDEO0_4X>,
				<&ccu CLK_ISP>, <&ccu CLK_PLL_VIDEO0_4X>,
				<&ccu CLK_BUS_CSI>, <&ccu CLK_CSI_MBUS_GATE>, <&ccu CLK_ISP_MBUS_GATE>, <&ccu CLK_BUS_ISP>;
			clock-names = "csi_top", "csi_top_src",
						"csi_mclk0", "csi_mclk0_24m", "csi_mclk0_pll",
						"csi_mclk1", "csi_mclk1_24m", "csi_mclk1_pll",
						"csi_mclk2", "csi_mclk2_24m", "csi_mclk2_pll",
						"csi_mclk3", "csi_mclk3_24m", "csi_mclk3_pll",
						"csi_isp", "csi_isp_src",
						"csi_bus", "csi_mbus", "csi_isp_mbus", "isp_bus";
			resets = <&ccu RST_BUS_CSI>, <&ccu RST_BUS_ISP>;
			reset-names = "csi_ret", "isp_ret";
			pinctrl-names = "mclk0-default", "mclk0-sleep", "mclk1-default", "mclk1-sleep",
							"mclk2-default", "mclk2-sleep", "mclk3-default", "mclk3-sleep";
			pinctrl-0 = <&csi_mclk0_pins_a>;
			pinctrl-1 = <&csi_mclk0_pins_b>;
			pinctrl-2 = <&csi_mclk1_pins_a>;
			pinctrl-3 = <&csi_mclk1_pins_b>;
			pinctrl-4 = <&csi_mclk2_pins_a>;
			pinctrl-5 = <&csi_mclk2_pins_b>;
			pinctrl-6 = <&csi_mclk3_pins_a>;
			pinctrl-7 = <&csi_mclk3_pins_b>;
			//power-domains = <>;
			dram_dfs_time = <>;
			status = "okay";

			csi0: csi@5820000 {
				compatible = "allwinner,sunxi-csi";
				reg = <0x0 0x05820000 0x0 0x1000>;
				interrupts = <GIC_SPI 130 IRQ_TYPE_LEVEL_HIGH>;
				device_id = <0>;
				status = "okay";
			};
			csi1: csi@5821000 {
				compatible = "allwinner,sunxi-csi";
				reg = <0x0 0x05821000 0x0 0x1000>;
				interrupts = <GIC_SPI 131 IRQ_TYPE_LEVEL_HIGH>;
				device_id = <1>;
				status = "okay";
			};
			csi2: csi@5822000 {
				compatible = "allwinner,sunxi-csi";
				reg = <0x0 0x05822000 0x0 0x1000>;
				interrupts = <GIC_SPI 132 IRQ_TYPE_LEVEL_HIGH>;
				device_id = <2>;
				status = "okay";
			};
			csi3: csi@5823000 {
				compatible = "allwinner,sunxi-csi";
				reg = <0x0 0x05823000 0x0 0x1000>;
				interrupts = <GIC_SPI 147 IRQ_TYPE_LEVEL_HIGH>;
				pinctrl-names = "default","sleep";
				pinctrl-0 = <&ncsi_bt656_pins_a>;
				pinctrl-1 = <&ncsi_bt656_pins_b>;
				device_id = <3>;
				status = "okay";
			};
			mipi0: mipi@5810100 {
				compatible = "allwinner,sunxi-mipi";
				reg = <0x0 0x05810100 0x0 0x100>,
					<0x0 0x05811000 0x0 0x400>;
				interrupts = <GIC_SPI 137 IRQ_TYPE_LEVEL_HIGH>;
				pinctrl-names = "mipi0-default","mipi0-sleep",
						"mipi1-4lane-default","mipi1-4lane-sleep";
				pinctrl-0 = <&mipia_pins_a>;
				pinctrl-1 = <&mipia_pins_b>;
				pinctrl-2 = <&mipib_4lane_pins_a>;
				pinctrl-3 = <&mipib_4lane_pins_b>;
				device_id = <0>;
				status = "okay";
			};
			mipi1: mipi@5810200 {
				compatible = "allwinner,sunxi-mipi";
				reg = <0x0 0x05810200 0x0 0x100>,
					<0x0 0x05811400 0x0 0x400>;
				pinctrl-names = "mipi1-default","mipi1-sleep";
				pinctrl-0 = <&mipib_pins_a>;
				pinctrl-1 = <&mipib_pins_b>;
				device_id = <1>;
				status = "okay";
			};
			mipi2: mipi@5810300 {
				compatible = "allwinner,sunxi-mipi";
				reg = <0x0 0x05810300 0x0 0x100>,
					<0x0 0x05811800 0x0 0x400>;
				pinctrl-names = "mipi2-default","mipi2-sleep",
						"mipi3-4lane-default","mipi3-4lane-sleep";
				pinctrl-0 = <&mipic_pins_a>;
				pinctrl-1 = <&mipic_pins_b>;
				pinctrl-2 = <&mipid_4lane_pins_a>;
				pinctrl-3 = <&mipid_4lane_pins_b>;
				device_id = <2>;
				status = "okay";
			};
			mipi3: mipi@5810400 {
				compatible = "allwinner,sunxi-mipi";
				reg = <0x0 0x05810400 0x0 0x100>,
					<0x0 0x05811C00 0x0 0x400>;
				pinctrl-names = "mipi3-default","mipi3-sleep";
				pinctrl-0 = <&mipid_pins_a>;
				pinctrl-1 = <&mipid_pins_b>;
				device_id = <3>;
				status = "okay";
			};
			tdm0: tdm@5908000 {
				compatible = "allwinner,sunxi-tdm";
				reg = <0x0 0x05908000 0x0 0x340>;
				interrupts = <GIC_SPI 138 IRQ_TYPE_LEVEL_HIGH>;
				work_mode = <0x0>;
				device_id = <0>;
				iommus = <&mmu_aw 0 0>;
				status = "okay";
			};
			isp00:isp@5900000 {
				compatible = "allwinner,sunxi-isp";
				reg = <0x0 0x05900000 0x0 0x1300>;
				interrupts = <GIC_SPI 133 IRQ_TYPE_LEVEL_HIGH>;
				work_mode = <0x0>;
				device_id = <0>;
				iommus = <&mmu_aw 0 0>;
				status = "okay";
			};
			isp01:isp@58ffffc {
				compatible = "allwinner,sunxi-isp";
				reg = <0x0 0x058ffffc 0x0 0x1304>;
				interrupts = <GIC_SPI 134 IRQ_TYPE_LEVEL_HIGH>;
				work_mode = <0xff>;
				device_id = <1>;
				iommus = <&mmu_aw 0 0>;
				status = "disabled";
			};
			isp02:isp@58ffff8 {
				compatible = "allwinner,sunxi-isp";
				reg = <0x0 0x058ffff8 0x0 0x1308>;
				interrupts = <GIC_SPI 135 IRQ_TYPE_LEVEL_HIGH>;
				work_mode = <0xff>;
				device_id = <2>;
				iommus = <&mmu_aw 0 0>;
				status = "disabled";
			};
			isp03:isp@58ffff4 {
				compatible = "allwinner,sunxi-isp";
				reg = <0x0 0x058ffff4 0x0 0x130c>;
				interrupts = <GIC_SPI 136 IRQ_TYPE_LEVEL_HIGH>;
				work_mode = <0xff>;
				device_id = <3>;
				iommus = <&mmu_aw 0 0>;
				status = "disabled";
			};
			isp10:isp@4 {
				compatible = "allwinner,sunxi-isp";
				device_id = <4>;
				iommus = <&mmu_aw 0 0>;
				status = "disabled";
			};
			isp20:isp@5 {
				compatible = "allwinner,sunxi-isp";
				device_id = <5>;
				iommus = <&mmu_aw 0 0>;
				status = "disabled";
			};
			isp30:isp@6 {
				compatible = "allwinner,sunxi-isp";
				device_id = <6>;
				iommus = <&mmu_aw 0 0>;
				status = "disabled";
			};
			scaler00:scaler@5910000 {
				compatible = "allwinner,sunxi-scaler";
				reg = <0x0 0x05910000 0x0 0x400>;
				interrupts = <GIC_SPI 126 IRQ_TYPE_LEVEL_HIGH>;
				work_mode = <0x0>;
				device_id = <0>;
				iommus = <&mmu_aw 1 0>;
				status = "okay";
			};
			scaler01:scaler@590fffc {
				compatible = "allwinner,sunxi-scaler";
				reg = <0x0 0x0590fffc 0x0 0x404>;
				work_mode = <0xff>;
				device_id = <1>;
				iommus = <&mmu_aw 1 0>;
				status = "disabled";
			};
			scaler02:scaler@590fff8 {
				compatible = "allwinner,sunxi-scaler";
				reg = <0x0 0x0590fff8 0x0 0x408>;
				work_mode = <0xff>;
				device_id = <2>;
				iommus = <&mmu_aw 1 0>;
				status = "disabled";
			};
			scaler03:scaler@590fff4 {
				compatible = "allwinner,sunxi-scaler";
				reg = <0x0 0x0590fff4 0x0 0x40c>;
				work_mode = <0xff>;
				device_id = <3>;
				iommus = <&mmu_aw 1 0>;
				status = "disabled";
			};
			scaler10:scaler@5910400 {
				compatible = "allwinner,sunxi-scaler";
				reg = <0x0 0x05910400 0x0 0x400>;
				interrupts = <GIC_SPI 127 IRQ_TYPE_LEVEL_HIGH>;
				work_mode = <0x0>;
				device_id = <4>;
				iommus = <&mmu_aw 1 0>;
				status = "disabled";
			};
			scaler11:scaler@59103fc {
				compatible = "allwinner,sunxi-scaler";
				reg = <0x0 0x059103fc 0x0 0x404>;
				work_mode = <0xff>;
				device_id = <5>;
				iommus = <&mmu_aw 1 0>;
				status = "disabled";
			};
			scaler12:scaler@59103f8 {
				compatible = "allwinner,sunxi-scaler";
				reg = <0x0 0x059103f8 0x0 0x408>;
				work_mode = <0xff>;
				device_id = <6>;
				iommus = <&mmu_aw 1 0>;
				status = "disabled";
			};
			scaler13:scaler@59103f4 {
				compatible = "allwinner,sunxi-scaler";
				reg = <0x0 0x059103f4 0x0 0x40c>;
				work_mode = <0xff>;
				device_id = <7>;
				iommus = <&mmu_aw 1 0>;
				status = "disabled";
			};
			scaler20:scaler@5910800 {
				compatible = "allwinner,sunxi-scaler";
				reg = <0x0 0x05910800 0x0 0x400>;
				interrupts = <GIC_SPI 128 IRQ_TYPE_LEVEL_HIGH>;
				work_mode = <0x0>;
				device_id = <8>;
				iommus = <&mmu_aw 1 0>;
				status = "disabled";
			};
			scaler21:scaler@59107fc {
				compatible = "allwinner,sunxi-scaler";
				reg = <0x0 0x059107fc 0x0 0x404>;
				work_mode = <0xff>;
				device_id = <9>;
				iommus = <&mmu_aw 1 0>;
				status = "disabled";
			};
			scaler22:scaler@59107f8 {
				compatible = "allwinner,sunxi-scaler";
				reg = <0x0 0x059107f8 0x0 0x408>;
				work_mode = <0xff>;
				device_id = <10>;
				iommus = <&mmu_aw 1 0>;
				status = "disabled";
			};
			scaler23:scaler@59107f4 {
				compatible = "allwinner,sunxi-scaler";
				reg = <0x0 0x059107f4 0x0 0x40c>;
				work_mode = <0xff>;
				device_id = <11>;
				iommus = <&mmu_aw 1 0>;
				status = "disabled";
			};
			scaler30:scaler@5910c00 {
				compatible = "allwinner,sunxi-scaler";
				reg = <0x0 0x05910c00 0x0 0x400>;
				interrupts = <GIC_SPI 129 IRQ_TYPE_LEVEL_HIGH>;
				work_mode = <0x0>;
				device_id = <12>;
				iommus = <&mmu_aw 1 0>;
				status = "disabled";
			};
			scaler31:scaler@5910bfc {
				compatible = "allwinner,sunxi-scaler";
				reg = <0x0 0x05910bfc 0x0 0x404>;
				work_mode = <0xff>;
				device_id = <13>;
				iommus = <&mmu_aw 1 0>;
				status = "disabled";
			};
			scaler32:scaler@5910bf8 {
				compatible = "allwinner,sunxi-scaler";
				reg = <0x0 0x05910bf8 0x0 0x408>;
				work_mode = <0xff>;
				device_id = <14>;
				iommus = <&mmu_aw 1 0>;
				status = "disabled";
			};
			scaler33:scaler@5910bf4 {
				compatible = "allwinner,sunxi-scaler";
				reg = <0x0 0x05910bf4 0x0 0x40c>;
				work_mode = <0xff>;
				device_id = <15>;
				iommus = <&mmu_aw 1 0>;
				status = "disabled";
			};
			actuator0: actuator@2108180 {
				compatible = "allwinner,sunxi-actuator";
				device_type = "actuator0";
				reg = <0x0 0x02108180 0x0 0x10>;
				actuator0_name = "ad5820_act";
				actuator0_slave = <0x18>;
				actuator0_af_pwdn = <>;
				actuator0_afvdd = "afvcc-csi";
				actuator0_afvdd_vol = <2800000>;
				status = "disabled";
			};
			flash0: flash@2108190 {
				device_type = "flash0";
				compatible = "allwinner,sunxi-flash";
				reg = <0x0 0x02108190 0x0 0x10>;
				flash0_type = <2>;
				flash0_en = <>;
				flash0_mode = <>;
				flash0_flvdd = "";
				flash0_flvdd_vol = <>;
				device_id = <0>;
				status = "disabled";
			};
			sensor0: sensor@5812000 {
				reg = <0x0 0x05812000 0x0 0x10>;
				device_type = "sensor0";
				compatible = "allwinner,sunxi-sensor";
				sensor0_mname = "ov5640";
				sensor0_twi_cci_id = <2>;
				sensor0_twi_addr = <0x78>;
				sensor0_mclk_id = <0>;
				sensor0_pos = "rear";
				sensor0_isp_used = <0>;
				sensor0_fmt = <0>;
				sensor0_stby_mode = <0>;
				sensor0_vflip = <0>;
				sensor0_hflip = <0>;
				sensor0_iovdd-supply = <>;
				sensor0_iovdd_vol = <>;
				sensor0_avdd-supply = <>;
				sensor0_avdd_vol = <>;
				sensor0_dvdd-supply = <>;
				sensor0_dvdd_vol = <>;
				sensor0_power_en = <>;
				sensor0_reset = <>;
				sensor0_pwdn = <>;
				sensor0_sm_vs = <>;
				flash_handle = <&flash0>;
				act_handle = <&actuator0>;
				device_id = <0>;
				status	= "disabled";
			};
			sensor1: sensor@5812010 {
				reg = <0x0 0x05812010 0x0 0x10>;
				device_type = "sensor1";
				compatible = "allwinner,sunxi-sensor";
				sensor1_mname = "ov5647";
				sensor1_twi_cci_id = <3>;
				sensor1_twi_addr = <0x6c>;
				sensor1_mclk_id = <1>;
				sensor1_pos = "front";
				sensor1_isp_used = <0>;
				sensor1_fmt = <0>;
				sensor1_stby_mode = <0>;
				sensor1_vflip = <0>;
				sensor1_hflip = <0>;
				sensor1_iovdd-supply = <>;
				sensor1_iovdd_vol = <>;
				sensor1_avdd-supply = <>;
				sensor1_avdd_vol = <>;
				sensor1_dvdd-supply = <>;
				sensor1_dvdd_vol = <>;
				sensor1_power_en = <>;
				sensor1_reset = <>;
				sensor1_pwdn = <>;
				sensor1_sm_vs = <>;
				flash_handle = <>;
				act_handle = <>;
				device_id = <1>;
				status	= "disabled";
			};
			sensor2: sensor@5812020 {
				reg = <0x0 0x05812020 0x0 0x10>;
				device_type = "sensor2";
				compatible = "allwinner,sunxi-sensor";
				sensor2_mname = "imx386_mipi";
				sensor2_twi_cci_id = <3>;
				sensor2_twi_addr = <0x6c>;
				sensor2_mclk_id = <1>;
				sensor2_pos = "rear";
				sensor2_isp_used = <0>;
				sensor2_fmt = <0>;
				sensor2_stby_mode = <0>;
				sensor2_vflip = <0>;
				sensor2_hflip = <0>;
				sensor2_iovdd-supply = <>;
				sensor2_iovdd_vol = <>;
				sensor2_avdd-supply = <>;
				sensor2_avdd_vol = <>;
				sensor2_dvdd-supply = <>;
				sensor2_dvdd_vol = <>;
				sensor2_power_en = <>;
				sensor2_reset = <>;
				sensor2_pwdn = <>;
				sensor2_sm_vs = <>;
				flash_handle = <>;
				act_handle = <>;
				device_id = <2>;
				status= "disabled";
			};
			sensor3: sensor@5812030 {
				reg = <0x0 0x05812030 0x0 0x10>;
				device_type = "sensor3";
				compatible = "allwinner,sunxi-sensor";
				sensor3_mname = "imx317_mipi";
				sensor3_twi_cci_id = <3>;
				sensor3_twi_addr = <0x6c>;
				sensor3_mclk_id = <1>;
				sensor3_pos = "rear";
				sensor3_isp_used = <0>;
				sensor3_fmt = <0>;
				sensor3_stby_mode = <0>;
				sensor3_vflip = <0>;
				sensor3_hflip = <0>;
				sensor3_iovdd-supply = <>;
				sensor3_iovdd_vol = <>;
				sensor3_avdd-supply = <>;
				sensor3_avdd_vol = <>;
				sensor3_dvdd-supply = <>;
				sensor3_dvdd_vol = <>;
				sensor3_power_en = <>;
				sensor3_reset = <>;
				sensor3_pwdn = <>;
				sensor3_sm_vs = <>;
				flash_handle = <>;
				act_handle = <>;
				device_id = <2>;
				status= "disabled";
			};
			sensor_list0:sensor_list@200b820 {
				reg = <0x0 0x0200b820 0x0 0x10>;
				device_type = "sensor_list0";
				compatible = "allwinner,sunxi-sensor-list";
				csi_sel = <0>;
				sensor00_mname = "gc5035_mipi";
				sensor00_twi_addr = <0x6c>;
				sensor00_type = <1>;
				sensor00_hflip =  <0>;
				sensor00_vflip = <0>;
				sensor00_act_used = <1>;
				sensor00_act_name = "";
				sensor00_act_twi_addr = <>;
				sensor01_mname = "ov5675_mipi";
				sensor01_twi_addr = <0x6c>;
				sensor01_type = <1>;
				sensor01_hflip =  <0>;
				sensor01_vflip = <0>;
				sensor01_act_used = <1>;
				sensor01_act_name = "dw9714_act";
				sensor01_act_twi_addr = <0x18>;
				sensor02_mname = "sp5409_mipi";
				sensor02_twi_addr = <0x78>;
				sensor02_type = <1>;
				sensor02_hflip =  <0>;
				sensor02_vflip = <0>;
				sensor02_act_used = <0>;
				sensor02_act_name = "dw9714_act";
				sensor02_act_twi_addr = <0x18>;
				device_id = <0>;
				status	= "disabled";
			};
			sensor_list1:sensor_list@200b830 {
				reg = <0x0 0x0200b830 0x0 0x10>;
				device_type = "sensor_list1";
				compatible = "allwinner,sunxi-sensor-list";
				csi_sel = <0>;
				sensor10_mname = "gc02m2_mipi";
				sensor10_twi_addr = <0x20>;
				sensor10_type = <1>;
				sensor10_hflip =  <0>;
				sensor10_vflip = <0>;
				sensor10_act_used = <1>;
				sensor10_act_name = "dw9714_act";
				sensor10_act_twi_addr = <0x18>;
				sensor11_mname = "ov02a10_mipi";
				sensor11_twi_addr = <0x7a>;
				sensor11_type = <1>;
				sensor11_hflip =  <1>;
				sensor11_vflip = <0>;
				sensor11_act_used = <0>;
				sensor11_act_name = "";
				sensor11_act_twi_addr = <>;
				sensor12_mname = "gc030a_mipi";
				sensor12_twi_addr = <0x42>;
				sensor12_type = <1>;
				sensor12_hflip =  <0>;
				sensor12_vflip = <0>;
				sensor12_act_used = <0>;
				sensor12_act_name = "";
				sensor12_act_twi_addr = <>;
				device_id = <1>;
				status	= "disabled";
			};
			vinc00:vinc@5830000 {
				device_type = "vinc0";
				compatible = "allwinner,sunxi-vin-core";
				reg = <0x0 0x05830000 0x0 0x1000>;
				interrupts = <GIC_SPI 122 IRQ_TYPE_LEVEL_HIGH>;
				vinc0_csi_sel = <3>;
				vinc0_mipi_sel = <0xff>;
				vinc0_isp_sel = <0>;
				vinc0_isp_tx_ch = <0>;
				vinc0_tdm_rx_sel = <0>;
				vinc0_rear_sensor_sel = <0>;
				vinc0_front_sensor_sel = <0>;
				vinc0_sensor_list = <0>;
				device_id = <0>;
				work_mode = <0x0>;
				iommus = <&mmu_aw 1 0>;
				status = "okay";
			};

			vinc01:vinc@582fffc {
				device_type = "vinc1";
				compatible = "allwinner,sunxi-vin-core";
				reg = <0x0 0x0582fffc 0x0 0x1004>;
				vinc1_csi_sel = <2>;
				vinc1_mipi_sel = <0xff>;
				vinc1_isp_sel = <1>;
				vinc1_isp_tx_ch = <1>;
				vinc1_tdm_rx_sel = <1>;
				vinc1_rear_sensor_sel = <0>;
				vinc1_front_sensor_sel = <0>;
				vinc1_sensor_list = <0>;
				device_id = <1>;
				work_mode = <0xff>;
				iommus = <&mmu_aw 1 0>;
				status = "disabled";
			};
			vinc02:vinc@582fff8 {
				device_type = "vinc2";
				compatible = "allwinner,sunxi-vin-core";
				reg = <0x0 0x0582fff8 0x0 0x1008>;
				vinc2_csi_sel = <2>;
				vinc2_mipi_sel = <0xff>;
				vinc2_isp_sel = <2>;
				vinc2_isp_tx_ch = <2>;
				vinc2_tdm_rx_sel = <2>;
				vinc2_rear_sensor_sel = <0>;
				vinc2_front_sensor_sel = <0>;
				vinc2_sensor_list = <0>;
				device_id = <2>;
				work_mode = <0xff>;
				iommus = <&mmu_aw 1 0>;
				status = "disabled";
			};

			vinc03:vinc@582fff4 {
				device_type = "vinc3";
				compatible = "allwinner,sunxi-vin-core";
				reg = <0x0 0x0582fff4 0x0 0x100c>;
				vinc3_csi_sel = <0>;
				vinc3_mipi_sel = <0xff>;
				vinc3_isp_sel = <0>;
				vinc3_isp_tx_ch = <0>;
				vinc3_tdm_rx_sel = <0>;
				vinc3_rear_sensor_sel = <1>;
				vinc3_front_sensor_sel = <1>;
				vinc3_sensor_list = <0>;
				device_id = <3>;
				work_mode = <0xff>;
				iommus = <&mmu_aw 1 0>;
				status = "disabled";
			};

			vinc10:vinc@5831000 {
				device_type = "vinc4";
				compatible = "allwinner,sunxi-vin-core";
				reg = <0x0 0x05831000 0x0 0x1000>;
				interrupts = <GIC_SPI 123 IRQ_TYPE_LEVEL_HIGH>;
				vinc4_csi_sel = <3>;
				vinc4_mipi_sel = <0xff>;
				vinc4_isp_sel = <0>;
				vinc4_isp_tx_ch = <0>;
				vinc4_tdm_rx_sel = <0>;
				vinc4_rear_sensor_sel = <0>;
				vinc4_front_sensor_sel = <0>;
				vinc4_sensor_list = <0>;
				device_id = <4>;
				work_mode = <0x0>;
				iommus = <&mmu_aw 1 0>;
				status = "disabled";
			};

			vinc11:vinc@5830ffc {
				device_type = "vinc5";
				compatible = "allwinner,sunxi-vin-core";
				reg = <0x0 0x05830ffc 0x0 0x1004>;
				vinc5_csi_sel = <2>;
				vinc5_mipi_sel = <0xff>;
				vinc5_isp_sel = <1>;
				vinc5_isp_tx_ch = <1>;
				vinc5_tdm_rx_sel = <1>;
				vinc5_rear_sensor_sel = <0>;
				vinc5_front_sensor_sel = <0>;
				vinc5_sensor_list = <0>;
				device_id = <5>;
				work_mode = <0xff>;
				iommus = <&mmu_aw 1 0>;
				status = "disabled";
			};

			vinc12:vinc@5830ff8 {
				device_type = "vinc6";
				compatible = "allwinner,sunxi-vin-core";
				reg = <0x0 0x05830ff8 0x0 0x1008>;
				vinc6_csi_sel = <2>;
				vinc6_mipi_sel = <0xff>;
				vinc6_isp_sel = <0>;
				vinc6_isp_tx_ch = <0>;
				vinc6_tdm_rx_sel = <0>;
				vinc6_rear_sensor_sel = <0>;
				vinc6_front_sensor_sel = <0>;
				vinc6_sensor_list = <0>;
				device_id = <6>;
				work_mode = <0xff>;
				iommus = <&mmu_aw 1 0>;
				status = "disabled";
			};

			vinc13:vinc@5830ff4 {
				device_type = "vinc7";
				compatible = "allwinner,sunxi-vin-core";
				reg = <0x0 0x05830ff4 0x0 0x100c>;
				vinc7_csi_sel = <2>;
				vinc7_mipi_sel = <0xff>;
				vinc7_isp_sel = <0>;
				vinc7_isp_tx_ch = <0>;
				vinc7_tdm_rx_sel = <0>;
				vinc7_rear_sensor_sel = <0>;
				vinc7_front_sensor_sel = <0>;
				vinc7_sensor_list = <0>;
				device_id = <7>;
				work_mode = <0xff>;
				iommus = <&mmu_aw 1 0>;
				status = "disabled";
			};

			vinc20:vinc@5832000 {
				device_type = "vinc8";
				compatible = "allwinner,sunxi-vin-core";
				reg = <0x0 0x05832000 0x0 0x1000>;
				interrupts = <GIC_SPI 124 IRQ_TYPE_LEVEL_HIGH>;
				vinc8_csi_sel = <2>;
				vinc8_mipi_sel = <0xff>;
				vinc8_isp_sel = <4>;
				vinc8_isp_tx_ch = <3>;
				vinc8_tdm_rx_sel = <3>;
				vinc8_rear_sensor_sel = <0>;
				vinc8_front_sensor_sel = <0>;
				vinc8_sensor_list = <0>;
				device_id = <8>;
				work_mode = <0x0>;
				iommus = <&mmu_aw 1 0>;
				status = "disabled";
			};

			vinc21:vinc@5831ffc {
				device_type = "vinc9";
				compatible = "allwinner,sunxi-vin-core";
				reg = <0x0 0x05831ffc 0x0 0x1004>;
				vinc9_csi_sel = <2>;
				vinc9_mipi_sel = <0xff>;
				vinc9_isp_sel = <0>;
				vinc9_isp_tx_ch = <0>;
				vinc9_tdm_rx_sel = <0>;
				vinc9_rear_sensor_sel = <0>;
				vinc9_front_sensor_sel = <0>;
				vinc9_sensor_list = <0>;
				device_id = <9>;
				work_mode = <0xff>;
				iommus = <&mmu_aw 1 0>;
				status = "disabled";
			};

			vinc22:vinc@5831ff8 {
				device_type = "vinc10";
				compatible = "allwinner,sunxi-vin-core";
				reg = <0x0 0x05831ff8 0x0 0x1008>;
				vinc10_csi_sel = <2>;
				vinc10_mipi_sel = <0xff>;
				vinc10_isp_sel = <0>;
				vinc10_isp_tx_ch = <0>;
				vinc10_tdm_rx_sel = <0>;
				vinc10_rear_sensor_sel = <0>;
				vinc10_front_sensor_sel = <0>;
				vinc10_sensor_list = <0>;
				device_id = <10>;
				work_mode = <0xff>;
				iommus = <&mmu_aw 1 0>;
				status = "disabled";
			};

			vinc23:vinc@5831ff4 {
				device_type = "vinc11";
				compatible = "allwinner,sunxi-vin-core";
				reg = <0x0 0x05831ff4 0x0 0x100c>;
				vinc11_csi_sel = <2>;
				vinc11_mipi_sel = <0xff>;
				vinc11_isp_sel = <0>;
				vinc11_isp_tx_ch = <0>;
				vinc11_tdm_rx_sel = <0>;
				vinc11_rear_sensor_sel = <0>;
				vinc11_front_sensor_sel = <0>;
				vinc11_sensor_list = <0>;
				device_id = <11>;
				work_mode = <0xff>;
				iommus = <&mmu_aw 1 0>;
				status = "disabled";
			};

			vinc30:vinc@5833000 {
				device_type = "vinc12";
				compatible = "allwinner,sunxi-vin-core";
				reg = <0x0 0x05833000 0x0 0x1000>;
				interrupts = <GIC_SPI 125 IRQ_TYPE_LEVEL_HIGH>;
				vinc12_csi_sel = <2>;
				vinc12_mipi_sel = <0xff>;
				vinc12_isp_sel = <0>;
				vinc12_isp_tx_ch = <0>;
				vinc12_tdm_rx_sel = <0>;
				vinc12_rear_sensor_sel = <0>;
				vinc12_front_sensor_sel = <0>;
				vinc12_sensor_list = <0>;
				device_id = <12>;
				work_mode = <0x0>;
				iommus = <&mmu_aw 1 0>;
				status = "disabled";
			};

			vinc31:vinc@5832ffc {
				device_type = "vinc13";
				compatible = "allwinner,sunxi-vin-core";
				reg = <0x0 0x05832ffc 0x0 0x1004>;
				vinc13_csi_sel = <2>;
				vinc13_mipi_sel = <0xff>;
				vinc13_isp_sel = <0>;
				vinc13_isp_tx_ch = <0>;
				vinc13_tdm_rx_sel = <0>;
				vinc13_rear_sensor_sel = <0>;
				vinc13_front_sensor_sel = <0>;
				vinc13_sensor_list = <0>;
				device_id = <13>;
				work_mode = <0xff>;
				iommus = <&mmu_aw 1 0>;
				status = "disabled";
			};

			vinc32:vinc@5832ff8 {
				device_type = "vinc14";
				compatible = "allwinner,sunxi-vin-core";
				reg = <0x0 0x05832ff8 0x0 0x1008>;
				vinc14_csi_sel = <2>;
				vinc14_mipi_sel = <0xff>;
				vinc14_isp_sel = <0>;
				vinc14_isp_tx_ch = <0>;
				vinc14_tdm_rx_sel = <0>;
				vinc14_rear_sensor_sel = <0>;
				vinc14_front_sensor_sel = <0>;
				vinc14_sensor_list = <0>;
				device_id = <14>;
				work_mode = <0xff>;
				iommus = <&mmu_aw 1 0>;
				status = "disabled";
			};

			vinc33:vinc@5832ff4 {
				device_type = "vinc15";
				compatible = "allwinner,sunxi-vin-core";
				reg = <0x0 0x05832ff4 0x0 0x100c>;
				vinc15_csi_sel = <2>;
				vinc15_mipi_sel = <0xff>;
				vinc15_isp_sel = <0>;
				vinc15_isp_tx_ch = <0>;
				vinc15_tdm_rx_sel = <0>;
				vinc15_rear_sensor_sel = <0>;
				vinc15_front_sensor_sel = <0>;
				vinc15_sensor_list = <0>;
				device_id = <15>;
				work_mode = <0xff>;
				iommus = <&mmu_aw 1 0>;
				status = "disabled";
			};
		};

		/* audio dirver module -> audio codec */
		codec:codec@2030000 {
			#sound-dai-cells = <0>;
			compatible	= "allwinner,sunxi-snd-codec";
			reg		= <0x0 0x02030000 0x0 0x320>;
			resets		= <&ccu RST_BUS_AUDIO_CODEC>;
			clocks		= <&ccu CLK_AUDIO_CODEC>,
					  <&ccu CLK_AUDIO_CODEC_DAC_1X>;
			clock-names	= "clk_bus_audio",
					  "clk_audio_dac";
			status = "disabled";
		};

		codec_plat:codec_plat {
			#sound-dai-cells = <0>;
			compatible	= "allwinner,sunxi-snd-plat-aaudio";
			dac-txdata	= <0x02030020>;
			dmas		= <&dma0 7>;
			dma-names	= "tx";
			playback-cma	= <128>;
			tx-fifo-size	= <128>;
			status = "disabled";
		};

		codec_mach:codec_mach {
			compatible = "allwinner,sunxi-snd-mach";
			soundcard-mach,name		= "audiocodec";
			soundcard-mach,pin-switches	= "LINEOUTL", "SPK";
			soundcard-mach,routing		= "LINEOUTL", "LINEOUTLP_PIN",
							  "LINEOUTL", "LINEOUTLN_PIN",
							  "SPK", "LINEOUTLP_PIN",
							  "SPK", "LINEOUTLN_PIN";
			soundcard-mach,playback-only;
			status = "disabled";
			soundcard-mach,cpu {
				sound-dai = <&codec_plat>;
			};
			soundcard-mach,codec {
				sound-dai = <&codec>;
				soundcard-mach,pll-fs	= <1>;
			};
		};

		/* audio dirver module -> owa */
		owa_plat:owa_plat@2036000 {
			#sound-dai-cells = <0>;
			compatible	= "allwinner,sunxi-snd-plat-owa";
			reg		= <0x0 0x02036000 0x0 0x5C>;
			interrupts	= <GIC_SPI 23 IRQ_TYPE_LEVEL_HIGH>;
			resets		= <&ccu RST_BUS_OWA>;
			clocks		= <&ccu CLK_OWA>,
					  <&ccu CLK_OWA_TX>,
					  <&ccu CLK_OWA_RX>;
			clock-names	= "clk_bus_owa",
					  "clk_owa_tx",
					  "clk_owa_rx";
			dmas		= <&dma0 2>, <&dma0 2>;
			dma-names	= "tx", "rx";
			playback-cma	= <128>;
			capture-cma	= <128>;
			tx-fifo-size	= <128>;
			rx-fifo-size	= <128>;
			status = "disabled";
		};

		owa_mach:owa_mach {
			compatible = "allwinner,sunxi-snd-mach";
			soundcard-mach,name = "sndowa";
			status = "disabled";
			soundcard-mach,cpu {
				sound-dai = <&owa_plat>;
			};
			soundcard-mach,codec {
			};
		};

		/* audio dirver module -> dmic */
		dmic_plat:dmic_plat@2031000 {
			#sound-dai-cells = <0>;
			compatible	= "allwinner,sunxi-snd-plat-dmic";
			reg		= <0x0 0x02031000 0x0 0x50>;
			resets		= <&ccu RST_BUS_DMIC>;
			clocks		= <&ccu CLK_BUS_DMIC>,
					  <&ccu CLK_DMIC>;
			clock-names	= "clk_bus_dmic",
					  "clk_dmic";
			dmas		= <&dma0 8>;
			dma-names	= "rx";
			capture-cma	= <128>;
			rx-fifo-size	= <128>;
			status = "disabled";
		};

		dmic_mach:dmic_mach{
			compatible = "allwinner,sunxi-snd-mach";
			soundcard-mach,name		= "snddmic";
			soundcard-mach,capture-only;
			status = "disabled";
			soundcard-mach,cpu {
				sound-dai = <&dmic_plat>;
			};
			soundcard-mach,codec {
			};
		};

		/* audio dirver module -> I2S/PCM */
		i2s0_plat:i2s0_plat@2032000 {
			#sound-dai-cells = <0>;
			compatible = "allwinner,sunxi-snd-plat-i2s";
			reg		= <0x0 0x02032000 0x0 0x7C>;
			resets		= <&ccu RST_BUS_I2SPCM0>;
			clocks		= <&ccu CLK_BUS_I2SPCM0>,
					  <&ccu CLK_I2SPCM0>;
			clock-names	= "clk_bus_i2s",
					  "clk_i2s";
			dmas		= <&dma0 3>, <&dma0 3>;
			dma-names	= "tx", "rx";
			playback-cma	= <128>;
			capture-cma	= <128>;
			tx-fifo-size	= <128>;
			rx-fifo-size	= <128>;
			status = "disabled";
		};

		i2s0_mach:i2s0_mach{
			compatible = "allwinner,sunxi-snd-mach";
			soundcard-mach,name		= "sndi2s0";
			soundcard-mach,format		= "i2s";
			soundcard-mach,slot-num		= <2>;
			soundcard-mach,slot-width	= <32>;
			status = "disabled";
			soundcard-mach,cpu {
				sound-dai = <&i2s0_plat>;
			};
			soundcard-mach,codec {
			};
		};

		i2s1_plat:i2s1_plat@2033000 {
			#sound-dai-cells = <0>;
			compatible = "allwinner,sunxi-snd-plat-i2s";
			reg		= <0x0 0x02033000 0x0 0x7C>;
			resets		= <&ccu RST_BUS_I2SPCM1>;
			clocks		= <&ccu CLK_BUS_I2SPCM1>,
					  <&ccu CLK_I2SPCM1>;
			clock-names	= "clk_bus_i2s",
					  "clk_i2s";
			dmas		= <&dma0 4>, <&dma0 4>;
			dma-names	= "tx", "rx";
			playback-cma	= <128>;
			capture-cma	= <128>;
			tx-fifo-size	= <128>;
			rx-fifo-size	= <128>;
			status = "disabled";
		};

		i2s1_mach:i2s1_mach{
			compatible = "allwinner,sunxi-snd-mach";
			soundcard-mach,name		= "sndi2s1";
			soundcard-mach,format		= "i2s";
			soundcard-mach,slot-num		= <2>;
			soundcard-mach,slot-width	= <32>;
			status = "disabled";
			soundcard-mach,cpu {
				sound-dai = <&i2s1_plat>;
			};
			soundcard-mach,codec {
			};
		};

		i2s2_plat:i2s2_plat@2034000 {
			#sound-dai-cells = <0>;
			compatible = "allwinner,sunxi-snd-plat-i2s";
			reg		= <0x0 0x02034000 0x0 0x7C>;
			resets		= <&ccu RST_BUS_I2SPCM2>;
			clocks		= <&ccu CLK_BUS_I2SPCM2>,
					  <&ccu CLK_I2SPCM2>;
			clock-names	= "clk_bus_i2s",
					  "clk_i2s";
			dmas		= <&dma0 5>, <&dma0 5>;
			dma-names	= "tx", "rx";
			playback-cma	= <128>;
			capture-cma	= <128>;
			tx-fifo-size	= <128>;
			rx-fifo-size	= <128>;
			status = "disabled";
		};

		i2s2_mach:i2s2_mach{
			compatible = "allwinner,sunxi-snd-mach";
			soundcard-mach,name		= "sndi2s2";
			soundcard-mach,format		= "i2s";
			soundcard-mach,slot-num		= <2>;
			soundcard-mach,slot-width	= <32>;
			status = "disabled";
			soundcard-mach,cpu {
				sound-dai = <&i2s2_plat>;
			};
			soundcard-mach,codec {
			};
		};

		i2s3_plat:i2s3_plat@2035000 {
			#sound-dai-cells = <0>;
			compatible = "allwinner,sunxi-snd-plat-i2s";
			reg		= <0x0 0x02035000 0x0 0x7C>;
			resets		= <&ccu RST_BUS_I2SPCM3>;
			clocks		= <&ccu CLK_BUS_I2SPCM3>,
					  <&ccu CLK_I2SPCM3>;
			clock-names	= "clk_bus_i2s",
					  "clk_i2s";
			dmas		= <&dma0 6>, <&dma0 6>;
			dma-names	= "tx", "rx";
			playback-cma	= <128>;
			capture-cma	= <128>;
			tx-fifo-size	= <128>;
			rx-fifo-size	= <128>;
			status = "disabled";
		};

		i2s3_mach:i2s3_mach{
			compatible = "allwinner,sunxi-snd-mach";
			soundcard-mach,name		= "sndi2s3";
			soundcard-mach,format		= "i2s";
			soundcard-mach,slot-num		= <2>;
			soundcard-mach,slot-width	= <32>;
			status = "disabled";
			soundcard-mach,cpu {
				sound-dai = <&i2s3_plat>;
			};
			soundcard-mach,codec {
			};
		};
	};
};


